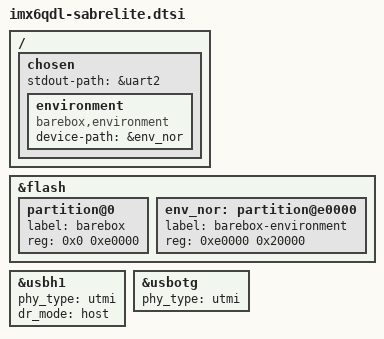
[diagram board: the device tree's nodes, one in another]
/*
 * Copyright 2011 Freescale Semiconductor, Inc.
 * Copyright 2011 Linaro Ltd.
 *
 * The code contained herein is licensed under the GNU General Public
 * License. You may obtain a copy of the GNU General Public License
 * Version 2 or later at the following locations:
 *
 * http://www.opensource.org/licenses/gpl-license.html
 * http://www.gnu.org/copyleft/gpl.html
 */
#include <dt-bindings/gpio/gpio.h>
#include <dt-bindings/input/input.h>
#include <arm/nxp/imx/imx6qdl-sabrelite.dtsi>

/ {

	chosen {
		stdout-path = &uart2;

		environment {
			compatible = "barebox,environment";
			device-path = &env_nor;
		};
	};
};

&flash {
	#address-cells = <1>;
	#size-cells = <1>;

	partition@0 {
		label = "barebox";
		reg = <0x0 0xe0000>;
	};

	env_nor: partition@e0000 {
		label = "barebox-environment";
		reg = <0xe0000 0x20000>;
	};
};

&usbh1 {
	phy_type = "utmi";
	dr_mode = "host";
};

&usbotg {
	phy_type = "utmi";
};
